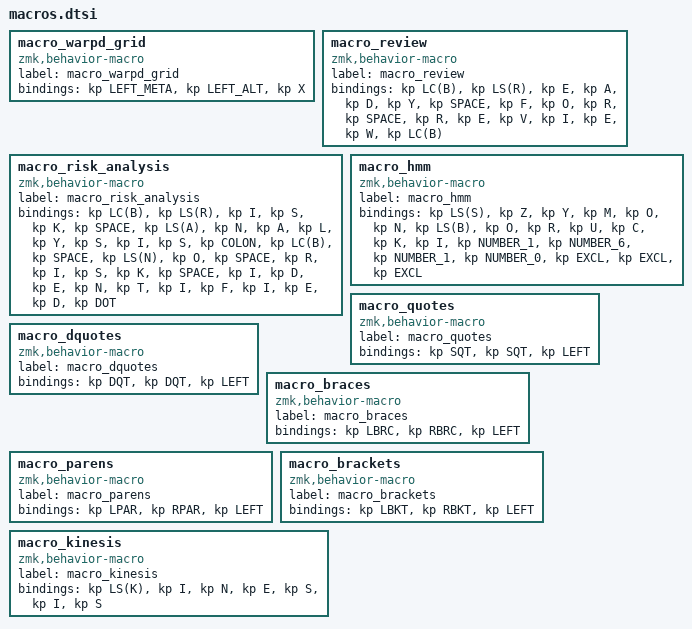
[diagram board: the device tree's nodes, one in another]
macro_warpd_grid: macro_warpd_grid{
compatible = "zmk,behavior-macro";
label = "macro_warpd_grid";
#binding-cells = <0>;
bindings = <&kp LEFT_META>, <&kp LEFT_ALT>, <&kp X>;
};
macro_review: macro_review{
compatible = "zmk,behavior-macro";
label = "macro_review";
#binding-cells = <0>;
bindings = <&kp LC(B)>, <&kp LS(R)>, <&kp E>, <&kp A>, <&kp D>, <&kp Y>, <&kp SPACE>, <&kp F>, <&kp O>, <&kp R>, <&kp SPACE>, <&kp R>, <&kp E>, <&kp V>, <&kp I>, <&kp E>, <&kp W>, <&kp LC(B)>;
};
macro_risk_analysis: macro_risk_analysis{
compatible = "zmk,behavior-macro";
label = "macro_risk_analysis";
#binding-cells = <0>;
bindings = <&kp LC(B)>, <&kp LS(R)>, <&kp I>, <&kp S>, <&kp K>, <&kp SPACE>, <&kp LS(A)>, <&kp N>, <&kp A>, <&kp L>, <&kp Y>, <&kp S>, <&kp I>, <&kp S>, <&kp COLON>, <&kp LC(B)>, <&kp SPACE>, <&kp LS(N)>, <&kp O>, <&kp SPACE>, <&kp R>, <&kp I>, <&kp S>, <&kp K>, <&kp SPACE>, <&kp I>, <&kp D>, <&kp E>, <&kp N>, <&kp T>, <&kp I>, <&kp F>, <&kp I>, <&kp E>, <&kp D>, <&kp DOT>;
};
macro_hmm: macro_hmm{
compatible = "zmk,behavior-macro";
label = "macro_hmm";
#binding-cells = <0>;
bindings = <&kp LS(S)>, <&kp Z>, <&kp Y>, <&kp M>, <&kp O>, <&kp N>, <&kp LS(B)>, <&kp O>, <&kp R>, <&kp U>, <&kp C>, <&kp K>, <&kp I>, <&kp NUMBER_1>, <&kp NUMBER_6>, <&kp NUMBER_1>, <&kp NUMBER_0>, <&kp EXCL>, <&kp EXCL>, <&kp EXCL>;
};
macro_quotes: macro_quotes{
compatible = "zmk,behavior-macro";
label = "macro_quotes";
#binding-cells = <0>;
bindings = <&kp SQT>, <&kp SQT>, <&kp LEFT>;
};
macro_dquotes: macro_dquotes{
compatible = "zmk,behavior-macro";
label = "macro_dquotes";
#binding-cells = <0>;
bindings = <&kp DQT>, <&kp DQT>, <&kp LEFT>;
};
macro_braces: macro_braces{
compatible = "zmk,behavior-macro";
label = "macro_braces";
#binding-cells = <0>;
bindings = <&kp LBRC>, <&kp RBRC>, <&kp LEFT>;
};
macro_parens: macro_parens{
compatible = "zmk,behavior-macro";
label = "macro_parens";
#binding-cells = <0>;
bindings = <&kp LPAR>, <&kp RPAR>, <&kp LEFT>;
};
macro_brackets: macro_brackets{
compatible = "zmk,behavior-macro";
label = "macro_brackets";
#binding-cells = <0>;
bindings = <&kp LBKT>, <&kp RBKT>, <&kp LEFT>;
};
macro_kinesis: macro_kinesis{
compatible = "zmk,behavior-macro";
label = "macro_kinesis";
#binding-cells = <0>;
bindings = <&kp LS(K)>, <&kp I>, <&kp N>, <&kp E>, <&kp S>, <&kp I>, <&kp S>;
};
